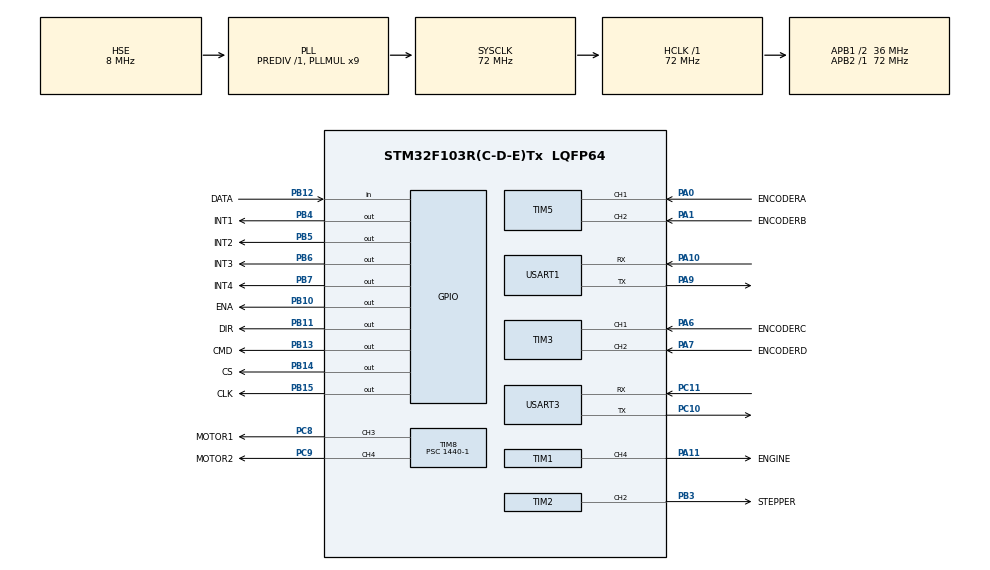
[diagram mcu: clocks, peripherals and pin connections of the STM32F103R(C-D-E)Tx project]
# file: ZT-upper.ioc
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Mcu.Family=STM32F1
Mcu.Name=STM32F103R(C-D-E)Tx
Mcu.Package=LQFP64
NVIC.PriorityGroup=NVIC_PRIORITYGROUP_4
NVIC.TIM3_IRQn=true\:4\:0\:true\:false\:true\:true\:true\:true
NVIC.TIM5_IRQn=true\:4\:0\:true\:false\:true\:true\:true\:true
NVIC.TIM7_IRQn=true\:3\:0\:true\:false\:true\:true\:true\:true
NVIC.USART1_IRQn=true\:1\:0\:true\:false\:true\:true\:true\:true
NVIC.USART3_IRQn=true\:2\:0\:true\:false\:true\:true\:true\:true
PA0-WKUP.GPIO_Label=ENCODERA
PA0-WKUP.Signal=S_TIM5_CH1
PA1.GPIO_Label=ENCODERB
PA1.Signal=S_TIM5_CH2
PA10.Mode=Asynchronous
PA10.Signal=USART1_RX
PA11.GPIO_Label=ENGINE
PA11.Signal=S_TIM1_CH4
PA13.Mode=Serial_Wire
PA13.Signal=SYS_JTMS-SWDIO
PA14.Mode=Serial_Wire
PA14.Signal=SYS_JTCK-SWCLK
PA6.GPIO_Label=ENCODERC
PA6.Signal=S_TIM3_CH1
PA7.GPIO_Label=ENCODERD
PA7.Signal=S_TIM3_CH2
PA9.Mode=Asynchronous
PA9.Signal=USART1_TX
PB10.GPIO_Label=ENA
PB10.Signal=GPIO_Output
PB11.GPIO_Label=DIR
PB11.Signal=GPIO_Output
PB12.GPIO_Label=DATA
PB12.Signal=GPIO_Input
PB13.GPIO_Label=CMD
PB13.Signal=GPIO_Output
PB14.GPIO_Label=CS
PB14.Signal=GPIO_Output
PB15.GPIO_Label=CLK
PB15.Signal=GPIO_Output
PB3.GPIO_Label=STEPPER
PB3.Signal=S_TIM2_CH2
PB4.GPIO_Label=INT1
PB4.Signal=GPIO_Output
PB5.GPIO_Label=INT2
PB5.Signal=GPIO_Output
PB6.GPIO_Label=INT3
PB6.Signal=GPIO_Output
PB7.GPIO_Label=INT4
PB7.Signal=GPIO_Output
PC10.Mode=Asynchronous
PC10.Signal=USART3_TX
PC11.Mode=Asynchronous
PC11.Signal=USART3_RX
PC8.GPIO_Label=MOTOR1
PC8.Signal=S_TIM8_CH3
PC9.GPIO_Label=MOTOR2
PC9.Signal=S_TIM8_CH4
PD0-OSC_IN.Mode=HSE-External-Oscillator
PD0-OSC_IN.Signal=RCC_OSC_IN
PD1-OSC_OUT.Mode=HSE-External-Oscillator
PD1-OSC_OUT.Signal=RCC_OSC_OUT
ProjectManager.HeapSize=0x200
ProjectManager.StackSize=0x400
ProjectManager.TargetToolchain=MDK-ARM V5.32
RCC.AHBFreq_Value=72000000
RCC.APB1CLKDivider=RCC_HCLK_DIV2
RCC.APB1Freq_Value=36000000
RCC.APB1TimFreq_Value=72000000
RCC.APB2Freq_Value=72000000
RCC.APB2TimFreq_Value=72000000
RCC.HCLKFreq_Value=72000000
RCC.PLLMUL=RCC_PLL_MUL9
RCC.PLLSourceVirtual=RCC_PLLSOURCE_HSE
RCC.SYSCLKFreq_VALUE=72000000
RCC.SYSCLKSource=RCC_SYSCLKSOURCE_PLLCLK
RCC.USBFreq_Value=72000000
SH.S_TIM1_CH4.0=TIM1_CH4,PWM Generation4 CH4
SH.S_TIM2_CH2.0=TIM2_CH2,PWM Generation2 CH2
SH.S_TIM3_CH1.0=TIM3_CH1,Encoder_Interface
SH.S_TIM3_CH2.0=TIM3_CH2,Encoder_Interface
SH.S_TIM5_CH1.0=TIM5_CH1,Encoder_Interface
SH.S_TIM5_CH2.0=TIM5_CH2,Encoder_Interface
SH.S_TIM8_CH3.0=TIM8_CH3,PWM Generation3 CH3
SH.S_TIM8_CH4.0=TIM8_CH4,PWM Generation4 CH4
TIM1.Channel-PWM\ Generation4\ CH4=TIM_CHANNEL_4
TIM1.Period=2000-1
TIM1.Prescaler=720-1
TIM2.Channel-PWM\ Generation2\ CH2=TIM_CHANNEL_2
TIM2.Period=1000-1
TIM2.Prescaler=72-1
TIM7.Period=500-1
TIM7.Prescaler=7200-1
TIM8.Channel-PWM\ Generation3\ CH3=TIM_CHANNEL_3
TIM8.Channel-PWM\ Generation4\ CH4=TIM_CHANNEL_4
TIM8.Period=1000-1
TIM8.Prescaler=1440-1
USART1.VirtualMode=VM_ASYNC
USART3.VirtualMode=VM_ASYNC
VP_TIM1_VS_ClockSourceINT.Mode=Internal
VP_TIM2_VS_ClockSourceINT.Mode=Internal
VP_TIM7_VS_ClockSourceINT.Mode=Enable_Timer
VP_TIM8_VS_ClockSourceINT.Mode=Internal
board=custom

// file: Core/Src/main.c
/* USER CODE BEGIN Header */
#include "encoder.h"
#include "motor.h"
#include "engine.h"
#include "stepper.h"
#include "ps2.h"
/**
  ******************************************************************************
  * @file           : main.c
  * @brief          : Main program body
  ******************************************************************************
  * @attention
  *
  * Copyright (c) 2023 STMicroelectronics.
  * All rights reserved.
  *
  * This software is licensed under terms that can be found in the LICENSE file
  * in the root directory of this software component.
  * If no LICENSE file comes with this software, it is provided AS-IS.
  *
  ******************************************************************************
  */
/* USER CODE END Header */
#include "main.h"
#include "tim.h"
#include "usart.h"
#include "gpio.h"

void SystemClock_Config(void);

int main(void)
{

  /* MCU Configuration--------------------------------------------------------*/

  /* Reset of all peripherals, Initializes the Flash interface and the Systick. */
  HAL_Init();

  /* Configure the system clock */
  SystemClock_Config();

  /* Initialize all configured peripherals */
  MX_GPIO_Init();
  MX_TIM1_Init();
  MX_TIM2_Init();
  MX_TIM3_Init();
  MX_TIM5_Init();
  MX_TIM7_Init();
  MX_TIM8_Init();
  MX_USART1_UART_Init();
  MX_USART3_UART_Init();
  /* USER CODE BEGIN 2 */
  Usart_init();
  Motor_init();
  Engine_init();
  Stepper_init();
  /* USER CODE END 2 */

  /* Infinite loop */
  while (1)
  {

    /* USER CODE BEGIN 3 */
    PS2_Control();
  }
  /* USER CODE END 3 */
}

void SystemClock_Config(void)
{
  RCC_OscInitTypeDef RCC_OscInitStruct = {0};
  RCC_ClkInitTypeDef RCC_ClkInitStruct = {0};

  /** Initializes the RCC Oscillators according to the specified parameters
  * in the RCC_OscInitTypeDef structure.
  */
  RCC_OscInitStruct.OscillatorType = RCC_OSCILLATORTYPE_HSE;
  RCC_OscInitStruct.HSEState = RCC_HSE_ON;
  RCC_OscInitStruct.HSEPredivValue = RCC_HSE_PREDIV_DIV1;
  RCC_OscInitStruct.HSIState = RCC_HSI_ON;
  RCC_OscInitStruct.PLL.PLLState = RCC_PLL_ON;
  RCC_OscInitStruct.PLL.PLLSource = RCC_PLLSOURCE_HSE;
  RCC_OscInitStruct.PLL.PLLMUL = RCC_PLL_MUL9;
  if (HAL_RCC_OscConfig(&RCC_OscInitStruct) != HAL_OK)
  {
    Error_Handler();
  }

  /** Initializes the CPU, AHB and APB buses clocks
  */
  RCC_ClkInitStruct.ClockType = RCC_CLOCKTYPE_HCLK|RCC_CLOCKTYPE_SYSCLK
                              |RCC_CLOCKTYPE_PCLK1|RCC_CLOCKTYPE_PCLK2;
  RCC_ClkInitStruct.SYSCLKSource = RCC_SYSCLKSOURCE_PLLCLK;
  RCC_ClkInitStruct.AHBCLKDivider = RCC_SYSCLK_DIV1;
  RCC_ClkInitStruct.APB1CLKDivider = RCC_HCLK_DIV2;
  RCC_ClkInitStruct.APB2CLKDivider = RCC_HCLK_DIV1;

  if (HAL_RCC_ClockConfig(&RCC_ClkInitStruct, FLASH_LATENCY_2) != HAL_OK)
  {
    Error_Handler();
  }
}

void Error_Handler(void)
{
  __disable_irq();
  while (1)
  {
  }
}
